# RC__RAM_Control_Module_1 register map
Vendor: Texas Instruments
Peripheral module from a debugger description file (folder msp430).
Registers are 16-bit, read-write, reset 0x0 unless marked. A register's access mark holds for its fields unless they carry their own. Offsets are as the file gives them; lines under a group give offsets from that group; [hi:lo] are bit positions; {n}, {i} and the like mark numbered series; 'fields as' and 'values as' point back to an identical list; <NAME> marks a mode.

## RC_RAM_Control_Module
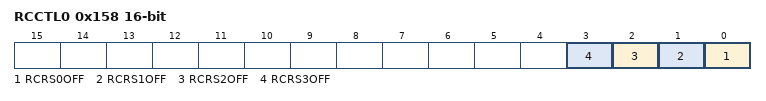
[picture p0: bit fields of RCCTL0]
0x158 RCCTL0 — Ram Controller Control Register
  [n] RCRS{n}OFF (n=0..3) — RAM Controller RAM Sector {n} Off
